VERSION "NexusCAN_EV_Powertrain_v1.0"

NS_ :

BS_:

BU_: VCU INV BMS OBC DCFC

VAL_TABLE_ vt_GearState 0 "Park" 1 "Reverse" 2 "Neutral" 3 "Drive" 4 "Sport" 15 "SNA" ;
VAL_TABLE_ vt_InverterState 0 "Init" 1 "Standby" 2 "Precharge" 3 "TorqueControl" 4 "SpeedControl" 5 "RegenBraking" 6 "ActiveDischarge" 14 "Derating" 15 "FaultLatch" ;
VAL_TABLE_ vt_FaultCode 0 "NoFault" 1 "OverCurrent" 2 "OverVoltage" 3 "UnderVoltage" 4 "OverTempIGBT" 5 "OverTempMotor" 6 "ResolverLoss" 7 "WatchdogTimeout" 8 "IsolationFault" ;
VAL_TABLE_ vt_ContactorState 0 "AllOpen" 1 "NegClosed_Precharging" 2 "AllClosed_HVActive" 3 "OpeningUnderLoad" 7 "WeldedFault" ;
VAL_TABLE_ vt_ChargingState 0 "NotConnected" 1 "CableCheck" 2 "Precharge" 3 "ConstantCurrent" 4 "ConstantVoltage" 5 "ChargeComplete" 6 "EmergencyShutdown" 7 "ChargerFault" ;
VAL_TABLE_ vt_CableLockState 0 "Unlocked" 1 "Locked" 2 "ActuatorError" 3 "NotAvailable" ;

BO_ 3221225472 VECTOR__INDEPENDENT_SIG_MSG: 0 Vector__XXX
 SG_ LegacyObdVehicleSpeedKph : 0|8@1+ (1,0) [0|255] "km/h" Vector__XXX
 SG_ UnmappedBenchDebugVoltage : 0|16@1+ (0.01,0) [0|655.35] "V" Vector__XXX

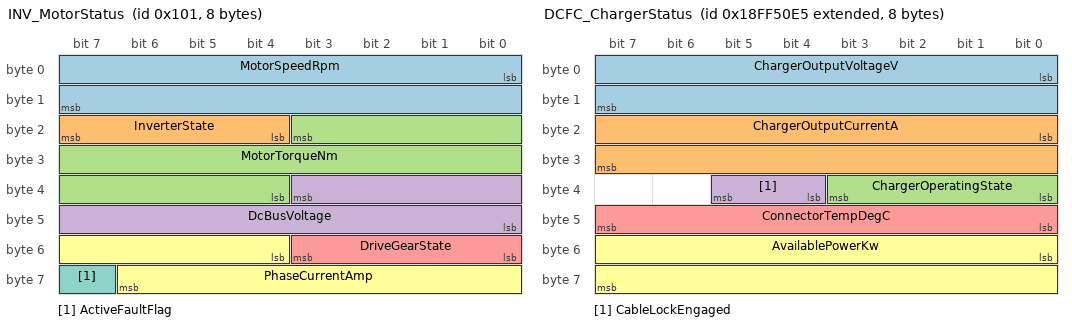
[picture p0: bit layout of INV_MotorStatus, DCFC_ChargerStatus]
BO_ 257 INV_MotorStatus: 8 INV
 SG_ MotorSpeedRpm : 0|16@1- (0.5,0) [-16000|16000] "rpm" VCU,BMS
 SG_ InverterState : 23|4@0+ (1,0) [0|15] "" VCU,BMS
 SG_ MotorTorqueNm : 19|16@0- (0.1,0) [-500|500] "Nm" VCU,BMS
 SG_ DcBusVoltage : 35|12@0+ (0.25,0) [0|1000] "V" VCU,BMS,OBC
 SG_ DriveGearState : 48|4@1+ (1,0) [0|15] "" VCU
 SG_ PhaseCurrentAmp : 52|11@1- (0.5,0) [-500|500] "A" VCU,BMS
 SG_ ActiveFaultFlag : 63|1@1+ (1,0) [0|1] "" VCU,BMS

BO_ 261 BMS_MuxDiagnostics: 8 BMS
 SG_ MuxDomainSwitch M : 0|4@1+ (1,0) [0|15] "" VCU,INV,OBC
 SG_ PackSocPct : 8|8@1+ (0.5,0) [0|100] "%" VCU,INV,OBC,DCFC
 SG_ SubBankSwitch m0M : 4|4@1+ (1,0) [0|15] "" VCU
 SG_ CellBank0MinMv m0 : 16|16@1+ (0.1,0) [0|5000] "mV" VCU
 SG_ CellBank0MaxMv m0 : 32|16@1+ (0.1,0) [0|5000] "mV" VCU
 SG_ CellBank0TempDegC m0 : 48|16@1- (0.01,0) [-40|125] "degC" VCU
 SG_ CellBank1MinMv m1 : 16|16@1+ (0.1,0) [0|5000] "mV" VCU
 SG_ CellBank1MaxMv m1 : 32|16@1+ (0.1,0) [0|5000] "mV" VCU
 SG_ CellBank1TempDegC m1 : 48|16@1- (0.01,0) [-40|125] "degC" VCU
 SG_ ContactorState m2 : 4|4@1+ (1,0) [0|7] "" VCU,INV,DCFC
 SG_ IsoResistanceKOhm m2 : 16|16@1+ (0.5,0) [0|32767.5] "kOhm" VCU,DCFC
 SG_ HvPackVoltageV m2 : 32|16@1+ (0.05,0) [0|1500] "V" VCU,INV,OBC,DCFC
 SG_ BmsFaultCode m2 : 48|8@1+ (1,0) [0|255] "" VCU,INV
 SG_ HvInterlockClosed m2 : 56|1@1+ (1,0) [0|1] "" VCU,INV

BO_ 513 INV_FastTelemetryFD: 64 INV
 SG_ E2E_Crc16 : 0|16@1+ (1,0) [0|65535] "" VCU
 SG_ E2E_AliveCounter : 16|4@1+ (1,0) [0|15] "" VCU
 SG_ E2E_DataId : 20|4@1+ (1,0) [0|15] "" VCU
 SG_ ControlLoopTickUs : 32|32@1+ (1,0) [0|4294967295] "us" VCU
 SG_ FluxLinkageWb : 64|32@1- (1,0) [-10|10] "Wb" VCU
 SG_ TotalEnergyKwh : 128|64@1- (1,0) [0|1000000] "kWh" VCU,BMS
 SG_ SubFrameSlotId : 263|4@0+ (1,0) [0|15] "" VCU
 SG_ ShaftTorqueFineNm : 259|16@0- (0.01,0) [-320|320] "Nm" VCU
 SG_ ResolverQualityPct : 275|12@0+ (0.025,0) [0|100] "%" VCU
 SG_ SiCBridgeTempMaxDegC : 488|16@1- (0.01,0) [-40|250] "degC" VCU,BMS
 SG_ TailIntegrityMarker : 504|8@1+ (1,0) [0|255] "" VCU

BO_ 2566869221 DCFC_ChargerStatus: 8 DCFC
 SG_ ChargerOutputVoltageV : 0|16@1+ (0.1,0) [0|1500] "V" BMS,VCU,OBC
 SG_ ChargerOutputCurrentA : 16|16@1+ (0.1,-1000) [-1000|1000] "A" BMS,VCU,OBC
 SG_ ChargerOperatingState : 32|4@1+ (1,0) [0|15] "" BMS,VCU
 SG_ CableLockEngaged : 36|2@1+ (1,0) [0|3] "" BMS,VCU
 SG_ ConnectorTempDegC : 40|8@1+ (1,-40) [-40|210] "degC" BMS,VCU
 SG_ AvailablePowerKw : 48|16@1+ (0.1,0) [0|1000] "kW" BMS,VCU

BO_TX_BU_ 257 : INV,VCU;
BO_TX_BU_ 261 : BMS,VCU;

CM_ "NexusCAN Golden Reference EV Powertrain, SiC Inverter CAN-FD & J1939 DC Fast Charger Database.
Validates Intel (@1+/1-), Vector Motorola Sawtooth (@0+/0-), IEEE-754 Float32/Float64,
64-byte CAN-FD (0..511 bits), Cascaded SG_MUL_VAL_ Multiplexing, and 29-bit J1939 PGN 0xFF50.";
CM_ BU_ VCU "Vehicle Control Unit — Primary torque arbitration, HV sequence coordinator,
and multi-bus gateway supervisor.";
CM_ BU_ INV "800V SiC Traction Inverter — High-rate FOC torque controller supporting
Classical CAN status frames (0x101) and 64-byte CAN-FD fast telemetry (0x201).";
CM_ BU_ BMS "High-Voltage Battery Management System — Pack state estimator, isolation monitor,
and cascaded multiplexer diagnostics publisher (0x105).";
CM_ BU_ OBC "Bidirectional On-Board AC Charger (11kW / 22kW) with V2L support.";
CM_ BU_ DCFC "Off-Board CCS / SAE J1939 DC Fast Charger broadcasting on 29-bit PGN 0xFF50 (SA 0xE5).";

CM_ BO_ 257 "10ms traction inverter primary status frame.
Combines Intel signed/unsigned cross-byte signals with unaligned 3-byte Vector Motorola sawtooth signals.";
CM_ BO_ 261 "20ms BMS cascaded multiplexer diagnostics frame.
Master switch MuxDomainSwitch selects Cell Bank Summary (domains 0..1 -> SubBankSwitch m0M)
or HV Isolation & Contactor diagnostics (domain 2).";
CM_ BO_ 513 "5ms 64-byte Standard CAN-FD high-rate inverter telemetry frame.
Exercises bit offsets 0..511, E2E SIG_GROUP_, IEEE-754 Float32/Float64, and high-byte Motorola sawtooth.";
CM_ BO_ 2566869221 "100ms Extended 29-bit SAE J1939 PGN 65360 (0xFF50) DC fast charger output status.";

CM_ SG_ 257 MotorSpeedRpm "Signed rotor mechanical speed (Intel 16-bit two's complement, 0.5 rpm/lsb).";
CM_ SG_ 257 MotorTorqueNm "Estimated electromagnetic shaft torque.
Encoded as unaligned 16-bit signed Motorola sawtooth spanning bytes 2, 3, and 4 (start bit 19).";
CM_ SG_ 257 DcBusVoltage "Inverter DC-link capacitor voltage (12-bit Motorola cross-byte unsigned).";
CM_ SG_ 257 PhaseCurrentAmp "11-bit signed Intel cross-byte RMS phase current.";
CM_ SG_ 261 MuxDomainSwitch "Top-level multiplexer selector:
0..1 = Cell Bank Sub-Multiplexer, 2 = Isolation & Contactors.";
CM_ SG_ 261 SubBankSwitch "Cascaded sub-multiplexer selector (m0M), active when MuxDomainSwitch is 0..1.";
CM_ SG_ 261 HvInterlockClosed "HVIL loop continuity status; active across domains 2..3 and 10..12 via SG_MUL_VAL_.";
CM_ SG_ 513 FluxLinkageWb "IEEE-754 single-precision float32 rotor flux linkage at bytes 8..11.";
CM_ SG_ 513 TotalEnergyKwh "IEEE-754 double-precision float64 cumulative delivered energy at bytes 16..23.";
CM_ SG_ 513 ShaftTorqueFineNm "High-resolution shaft torque using Motorola sawtooth across CAN-FD bytes 32..34.";
CM_ SG_ 513 TailIntegrityMarker "Final byte 63 marker spanning bits 504..511 to verify 512-bit CAN-FD boundary safety.";
CM_ SG_ 2566869221 ChargerOutputCurrentA "DC output current with J1939 -1000 A offset (raw 10000 = 0.0 A).";

BA_DEF_  "BusType" STRING ;
BA_DEF_ BU_  "NodeLayerModules" STRING ;
BA_DEF_ BO_  "VFrameFormat" ENUM  "StandardCAN","ExtendedCAN","StandardCAN_FD","ExtendedCAN_FD","J1939PG";
BA_DEF_ BO_  "GenMsgCycleTime" INT 0 60000;
BA_DEF_ SG_  "GenSigStartValue" FLOAT -1000000000 1000000000;
BA_DEF_ SG_  "SystemSignalLongSymbol" STRING ;

BA_DEF_DEF_  "BusType" "CAN FD";
BA_DEF_DEF_  "NodeLayerModules" "";
BA_DEF_DEF_  "VFrameFormat" "StandardCAN";
BA_DEF_DEF_  "GenMsgCycleTime" 0;
BA_DEF_DEF_  "GenSigStartValue" 0;
BA_DEF_DEF_  "SystemSignalLongSymbol" "";

BA_ "NodeLayerModules" BU_ VCU "CanNm,SecOC,DiagRouter";
BA_ "NodeLayerModules" BU_ INV "CanFdDriver,E2E_P01";
BA_ "NodeLayerModules" BU_ BMS "CanNm,IsoMonitor";
BA_ "NodeLayerModules" BU_ DCFC "J1939Tp,Din70121";

BA_ "GenMsgCycleTime" BO_ 257 10;
BA_ "GenMsgCycleTime" BO_ 261 20;
BA_ "VFrameFormat" BO_ 513 2;
BA_ "GenMsgCycleTime" BO_ 513 5;
BA_ "VFrameFormat" BO_ 2566869221 4;
BA_ "GenMsgCycleTime" BO_ 2566869221 100;

BA_ "GenSigStartValue" SG_ 257 DcBusVoltage 1600;
BA_ "GenSigStartValue" SG_ 261 PackSocPct 160;
BA_ "GenSigStartValue" SG_ 2566869221 ChargerOutputCurrentA 10000;
BA_ "GenSigStartValue" SG_ 2566869221 ConnectorTempDegC 65;

BA_ "SystemSignalLongSymbol" SG_ 257 MotorTorqueNm "InverterElectromagneticShaftTorqueEstimatedNm";
BA_ "SystemSignalLongSymbol" SG_ 513 FluxLinkageWb "PermanentMagnetRotorFluxLinkageWebers";
BA_ "SystemSignalLongSymbol" SG_ 513 TotalEnergyKwh "CumulativeInverterNetDeliveredEnergyKilowattHours";
BA_ "SystemSignalLongSymbol" SG_ 513 SiCBridgeTempMaxDegC "SiliconCarbidePowerModuleJunctionTemperatureMaximumDegC";

VAL_ 257 InverterState 0 "Init" 1 "Standby" 2 "Precharge" 3 "TorqueControl" 4 "SpeedControl" 5 "RegenBraking" 6 "ActiveDischarge" 14 "Derating" 15 "FaultLatch" ;
VAL_ 257 DriveGearState 0 "Park" 1 "Reverse" 2 "Neutral" 3 "Drive" 4 "Sport" 15 "SNA" ;
VAL_ 257 ActiveFaultFlag 0 "Normal" 1 "FaultActive" ;
VAL_ 261 ContactorState 0 "AllOpen" 1 "NegClosed_Precharging" 2 "AllClosed_HVActive" 3 "OpeningUnderLoad" 7 "WeldedFault" ;
VAL_ 261 BmsFaultCode 0 "NoFault" 1 "OverCurrent" 2 "OverVoltage" 3 "UnderVoltage" 4 "OverTempIGBT" 5 "OverTempMotor" 6 "ResolverLoss" 7 "WatchdogTimeout" 8 "IsolationFault" ;
VAL_ 261 HvInterlockClosed 0 "Open_Fault" 1 "Closed_OK" ;
VAL_ 2566869221 ChargerOperatingState 0 "NotConnected" 1 "CableCheck" 2 "Precharge" 3 "ConstantCurrent" 4 "ConstantVoltage" 5 "ChargeComplete" 6 "EmergencyShutdown" 7 "ChargerFault" ;
VAL_ 2566869221 CableLockEngaged 0 "Unlocked" 1 "Locked" 2 "ActuatorError" 3 "NotAvailable" ;

SIG_GROUP_ 513 E2E_FastTelemGroup 1 : E2E_Crc16 E2E_AliveCounter E2E_DataId;

SIG_VALTYPE_ 513 FluxLinkageWb : 1;
SIG_VALTYPE_ 513 TotalEnergyKwh : 2;

SG_MUL_VAL_ 261 SubBankSwitch MuxDomainSwitch 0-1;
SG_MUL_VAL_ 261 CellBank0MinMv SubBankSwitch 0-0;
SG_MUL_VAL_ 261 CellBank0MaxMv SubBankSwitch 0-0;
SG_MUL_VAL_ 261 CellBank0TempDegC SubBankSwitch 0-0;
SG_MUL_VAL_ 261 CellBank1MinMv SubBankSwitch 1-1;
SG_MUL_VAL_ 261 CellBank1MaxMv SubBankSwitch 1-1;
SG_MUL_VAL_ 261 CellBank1TempDegC SubBankSwitch 1-1;
SG_MUL_VAL_ 261 ContactorState MuxDomainSwitch 2-2;
SG_MUL_VAL_ 261 IsoResistanceKOhm MuxDomainSwitch 2-2;
SG_MUL_VAL_ 261 HvPackVoltageV MuxDomainSwitch 2-2;
SG_MUL_VAL_ 261 BmsFaultCode MuxDomainSwitch 2-2;
SG_MUL_VAL_ 261 HvInterlockClosed MuxDomainSwitch 2-3, 10-12;
